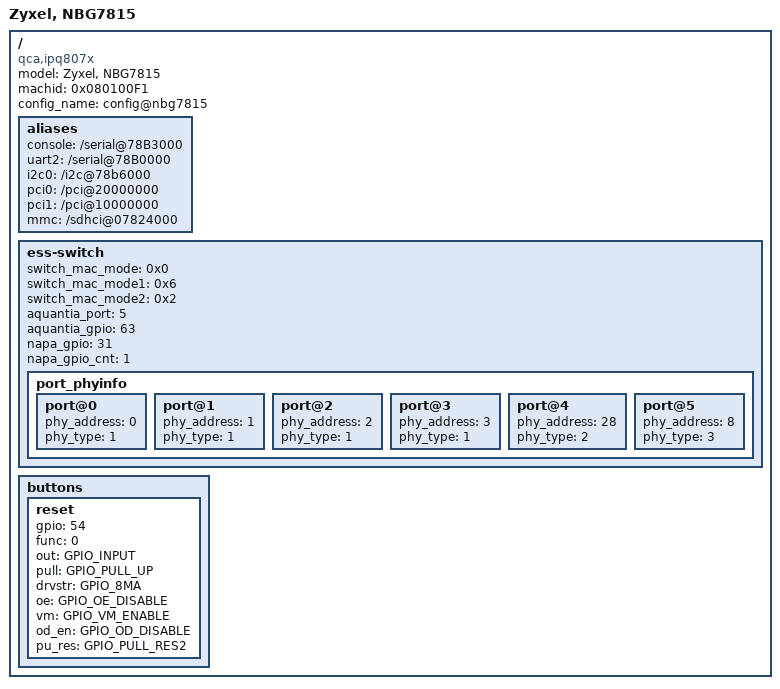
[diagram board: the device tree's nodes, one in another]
/*
 * Copyright (c) 2016, The Linux Foundation. All rights reserved.
 *
 * This program is free software; you can redistribute it and/or modify
 * it under the terms of the GNU General Public License version 2 and
 * only version 2 as published by the Free Software Foundation.
 *
 * This program is distributed in the hope that it will be useful,
 * but WITHOUT ANY WARRANTY; without even the implied warranty of
 * MERCHANTABILITY or FITNESS FOR A PARTICULAR PURPOSE.  See the
 * GNU General Public License for more details.
 */

/dts-v1/;
#include "ipq807x-soc.dtsi"
#include <dt-bindings/qcom/gpio-ipq807x.h>
/ {
	model ="Zyxel, NBG7815";
	compatible = "qca,ipq807x", "qca,ipq807x-hk01";
	machid = <0x080100F1>;
	config_name = "config@nbg7815";

	aliases {
		console = "/serial@78B3000";
		uart2 = "/serial@78B0000";
		i2c0 = "/i2c@78b6000";
		pci0 = "/pci@20000000";
		pci1 = "/pci@10000000";
		mmc = "/sdhci@07824000";
	};
	ess-switch {
		switch_mac_mode = <0x0>;
		switch_mac_mode1 = <0x6>;
		switch_mac_mode2 = <0x2>;
		aquantia_port = <5>;
		aquantia_gpio = <63>;
		napa_gpio = <31>;
		napa_gpio_cnt = <1>;
		port_phyinfo {
			port@0 {
				phy_address = <0>;
				phy_type = <1>;
			};
			port@1 {
				phy_address = <1>;
				phy_type = <1>;
			};
			port@2 {
				phy_address = <2>;
				phy_type = <1>;
			};
			port@3 {
				phy_address = <3>;
				phy_type = <1>;
			};
			port@4 {
				phy_address = <28>;
				phy_type = <2>;
			};
			port@5 {
				phy_address = <8>;
				phy_type = <3>;
			};
		};
	};

	buttons {
		reset {
			gpio = <54>;
			func = <0>;
			out = <GPIO_INPUT>;
			pull = <GPIO_PULL_UP>;
			drvstr = <GPIO_8MA>;
			oe = <GPIO_OE_DISABLE>;
			vm = <GPIO_VM_ENABLE>;
			od_en = <GPIO_OD_DISABLE>;
			pu_res = <GPIO_PULL_RES2>;
		};
	};

};

